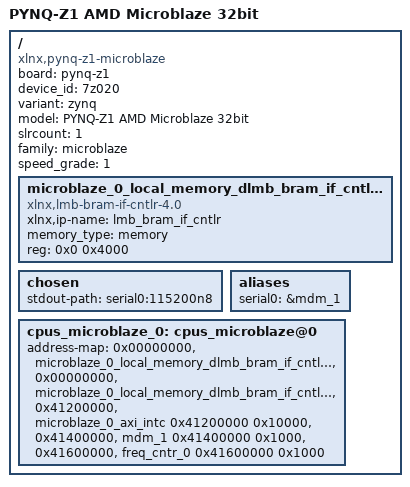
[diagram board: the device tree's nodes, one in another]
/dts-v1/;
#include "pl.dtsi"
/ {
	board = "pynq-z1";
	compatible = "xlnx,pynq-z1-microblaze";
	device_id = "7z020";
	#address-cells = <1>;
	variant = "zynq";
	model = "PYNQ-Z1 AMD Microblaze 32bit";
	#size-cells = <1>;
	slrcount = <1>;
	family = "microblaze";
	speed_grade = "1";
	microblaze_0_local_memory_dlmb_bram_if_cntlr_memory: memory@0 {
		ranges = <0 0x0 0x4000>;
		compatible = "xlnx,lmb-bram-if-cntlr-4.0" , "mmio-sram";
		#address-cells = <1>;
		xlnx,ip-name = "lmb_bram_if_cntlr";
		device_type = "memory";
		#size-cells = <1>;
		memory_type = "memory";
		reg = <0x0 0x4000>;
	};
	chosen {
		stdout-path = "serial0:115200n8";
	};
	aliases {
		serial0 = &mdm_1;
	};
	cpus_microblaze_0: cpus_microblaze@0 {
		address-map = <0x00000000 &microblaze_0_local_memory_dlmb_bram_if_cntlr_memory 0x00000000 0x4000>, 
			      <0x00000000 &microblaze_0_local_memory_dlmb_bram_if_cntlr 0x00000000 0x4000>, 
			      <0x41200000 &microblaze_0_axi_intc 0x41200000 0x10000>, 
			      <0x41400000 &mdm_1 0x41400000 0x1000>, 
			      <0x41600000 &freq_cntr_0 0x41600000 0x1000>;
		#ranges-address-cells = <0x1>;
		#ranges-size-cells = <0x1>;
	};
};
